VERSION ""

NS_ :

BS_:

BU_: XXX + HCU

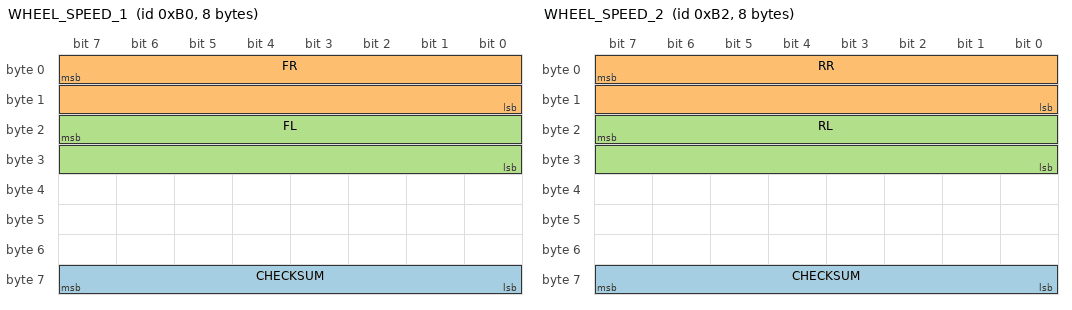
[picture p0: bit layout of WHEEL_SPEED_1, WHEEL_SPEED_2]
BO_ 176 WHEEL_SPEED_1: 8 XXX
 SG_ CHECKSUM : 63|8@0+ (1,0) [0|255] "" XXX
 SG_ FR : 7|16@0- (0.01,0) [0|250] "kph" XXX
 SG_ FL : 23|16@0- (0.01,0) [0|250] "kph" XXX

BO_ 178 WHEEL_SPEED_2: 8 XXX
 SG_ CHECKSUM : 63|8@0+ (1,0) [0|255] "" XXX
 SG_ RR : 7|16@0- (0.01,0) [0|250] "kph" XXX
 SG_ RL : 23|16@0- (0.01,0) [0|250] "kph" XXX

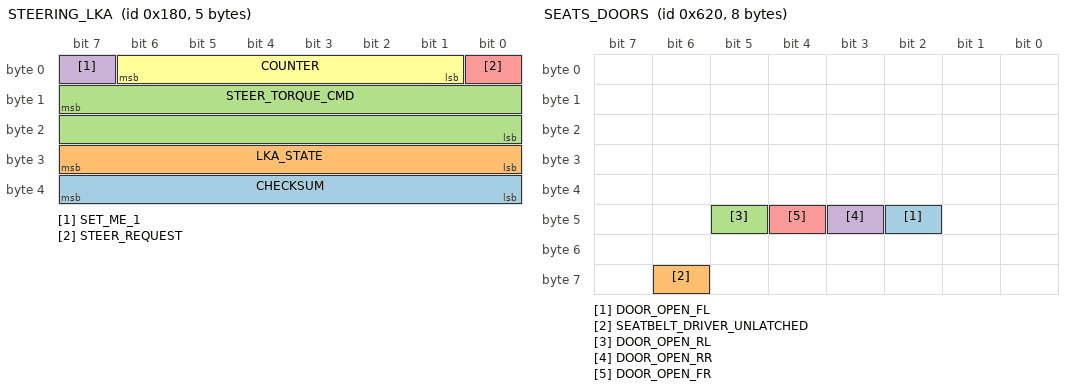
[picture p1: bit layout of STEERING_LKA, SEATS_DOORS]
BO_ 384 STEERING_LKA: 5 XXX
 SG_ CHECKSUM : 39|8@0+ (1,0) [0|255] "" XXX
 SG_ LKA_STATE : 31|8@0+ (1,0) [0|255] "" XXX
 SG_ STEER_TORQUE_CMD : 15|16@0- (1,0) [0|65535] "" XXX
 SG_ SET_ME_1 : 7|1@0+ (1,0) [0|1] "" XXX
 SG_ STEER_REQUEST : 0|1@0+ (1,0) [0|1] "" XXX
 SG_ COUNTER : 6|6@0+ (1,0) [0|63] "" XXX

BO_ 1568 SEATS_DOORS: 8 XXX
 SG_ DOOR_OPEN_FL : 42|1@0+ (1,0) [0|1] "" XXX
 SG_ SEATBELT_DRIVER_UNLATCHED : 62|1@0+ (1,0) [0|1] "" XXX
 SG_ DOOR_OPEN_RL : 45|1@0+ (1,0) [0|1] "" XXX
 SG_ DOOR_OPEN_RR : 43|1@0+ (1,0) [0|1] "" XXX
 SG_ DOOR_OPEN_FR : 44|1@0+ (1,0) [0|1] "" XXX

BO_ 37 STEER_ANGLE_SENSOR: 8 XXX
 SG_ STEER_ANGLE : 3|12@0- (1.5,0) [-500|500] "deg" XXX

BO_ 948 GEAR_PACKET: 8 XXX
 SG_ GEAR : 39|5@0+ (1,0) [0|15] "" XXX

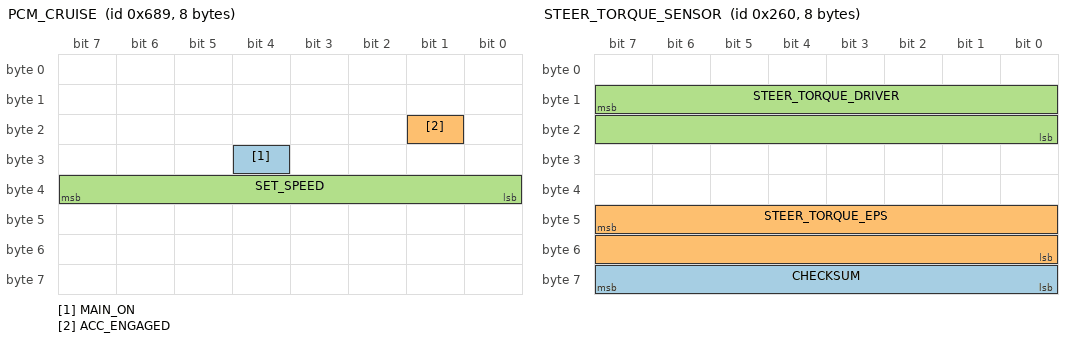
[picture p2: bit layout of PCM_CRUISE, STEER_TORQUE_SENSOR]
BO_ 1673 PCM_CRUISE: 8 XXX
 SG_ MAIN_ON : 28|1@0+ (1,0) [0|1] "" XXX
 SG_ ACC_ENGAGED : 17|1@0+ (1,0) [0|1] "" XXX
 SG_ SET_SPEED : 39|8@0+ (1,0) [0|255] "kph" XXX

BO_ 608 STEER_TORQUE_SENSOR: 8 XXX
 SG_ CHECKSUM : 63|8@0+ (1,0) [0|255] "" XXX
 SG_ STEER_TORQUE_EPS : 47|16@0- (1,0) [0|65535] "" XXX
 SG_ STEER_TORQUE_DRIVER : 15|16@0- (1,0) [-32768|32768] "" XXX

BO_ 184 BRAKE_MODULE3: 8 XXX
 SG_ BRAKE_PRESSURE : 43|12@0+ (1,0) [0|4095] "" XXX

BO_ 800 BRAKE_MODULE_2: 8 XXX
 SG_ BRAKE_PRESSED : 42|1@0+ (1,0) [0|1] "" XXX

BO_ 581 GAS_PEDAL: 8 XXX
 SG_ GAS_PEDAL : 16|8@1+ (1,0) [0|255] "" XXX

BO_ 1616 STEERING_LEVERS: 8 XXX
 SG_ TURN_SIGNALS : 31|2@0+ (1,0) [0|1] "" XXX

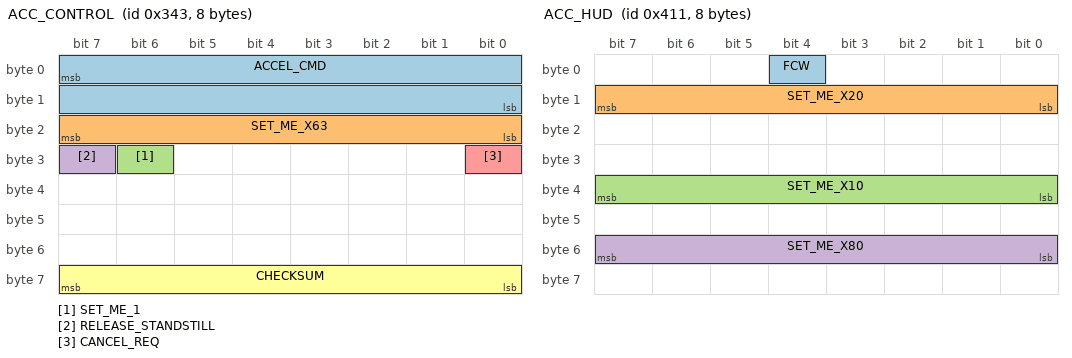
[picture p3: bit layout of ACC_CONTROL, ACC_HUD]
BO_ 835 ACC_CONTROL: 8 DSU
 SG_ ACCEL_CMD : 7|16@0- (0.001,0) [-20|20] "m/s2" HCU
 SG_ SET_ME_X63 : 23|8@0+ (1,0) [0|255] "" HCU
 SG_ SET_ME_1 : 30|1@0+ (1,0) [0|1] "" HCU
 SG_ RELEASE_STANDSTILL : 31|1@0+ (1,0) [0|1] "" HCU
 SG_ CANCEL_REQ : 24|1@0+ (1,0) [0|1] "" HCU
 SG_ CHECKSUM : 63|8@0+ (1,0) [0|255] "" XXX

BO_ 1041 ACC_HUD: 8 DSU
 SG_ FCW : 4|1@0+ (1,0) [0|1] "" XXX
 SG_ SET_ME_X20 : 15|8@0+ (1,0) [0|1] "" XXX
 SG_ SET_ME_X10 : 39|8@0+ (1,0) [0|1] "" XXX
 SG_ SET_ME_X80 : 55|8@0+ (1,0) [0|1] "" XXX

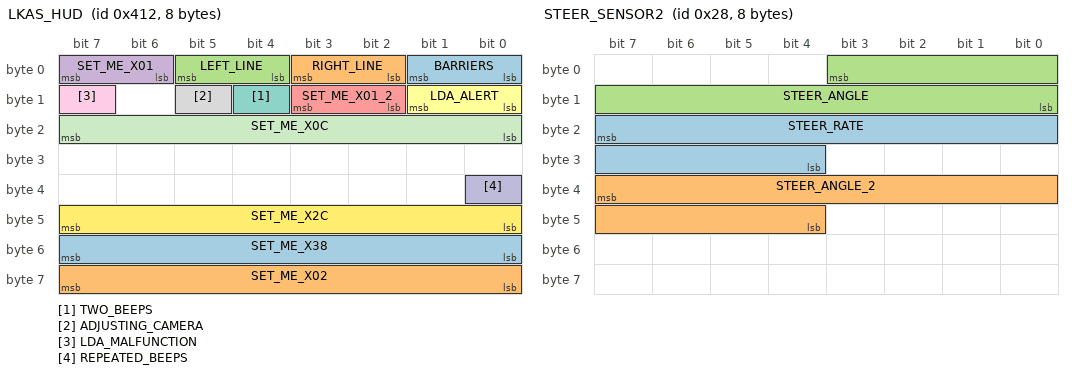
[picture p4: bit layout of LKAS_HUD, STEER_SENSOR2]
BO_ 1042 LKAS_HUD: 8 XXX
 SG_ BARRIERS : 1|2@0+ (1,0) [0|3] "" XXX
 SG_ RIGHT_LINE : 3|2@0+ (1,0) [0|3] "" XXX
 SG_ LEFT_LINE : 5|2@0+ (1,0) [0|3] "" XXX
 SG_ SET_ME_X01 : 7|2@0+ (1,0) [0|3] "" XXX
 SG_ SET_ME_X01_2 : 11|2@0+ (1,0) [0|3] "" XXX
 SG_ LDA_ALERT : 9|2@0+ (1,0) [0|3] "" XXX
 SG_ TWO_BEEPS : 12|1@0+ (1,0) [0|1] "" XXX
 SG_ ADJUSTING_CAMERA : 13|1@0+ (1,0) [0|1] "" XXX
 SG_ LDA_MALFUNCTION : 15|1@0+ (1,0) [0|1] "" XXX
 SG_ REPEATED_BEEPS : 32|1@0+ (1,0) [0|1] "" XXX
 SG_ SET_ME_X0C : 23|8@0+ (1,0) [0|1] "" XXX
 SG_ SET_ME_X2C : 47|8@0+ (1,0) [0|1] "" XXX
 SG_ SET_ME_X38 : 55|8@0+ (1,0) [0|1] "" XXX
 SG_ SET_ME_X02 : 63|8@0+ (1,0) [0|1] "" XXX

BO_ 560 BRAKE_MODULE2: 8 XXX
 SG_ BRAKE_PRESSED : 26|1@0+ (1,0) [0|1] "" XXX

BO_ 40 STEER_SENSOR2: 8 XXX
 SG_ STEER_RATE : 23|12@0- (1,0) [0|8191] "" XXX
 SG_ STEER_ANGLE_2 : 39|12@0- (1,0) [0|4095] "" XXX
 SG_ STEER_ANGLE : 3|12@0- (1,0) [0|8191] "" XXX

BO_ 548 BRAKE_MODULE: 8 XXX
 SG_ BRAKE_PRESSURE : 43|12@0+ (1,0) [0|4047] "" XXX
 SG_ BRAKE_PRESSED : 5|1@0+ (1,0) [0|1] "" XXX

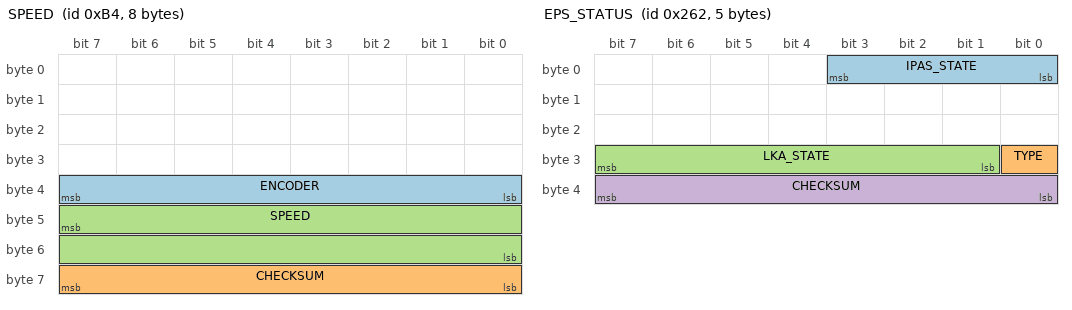
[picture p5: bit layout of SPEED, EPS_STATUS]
BO_ 180 SPEED: 8 XXX
 SG_ ENCODER : 39|8@0+ (1,0) [0|255] "" XXX
 SG_ CHECKSUM : 63|8@0+ (1,0) [0|255] "" XXX
 SG_ SPEED : 47|16@0+ (0.01,0) [0|250] "" XXX

BO_ 610 EPS_STATUS: 5 XXX
 SG_ IPAS_STATE : 3|4@0+ (1,0) [0|15] "" XXX
 SG_ TYPE : 24|1@0+ (1,0) [0|1] "" XXX
 SG_ LKA_STATE : 31|7@0+ (1,0) [0|127] "" XXX
 SG_ CHECKSUM : 39|8@0+ (1,0) [0|255] "" XXX

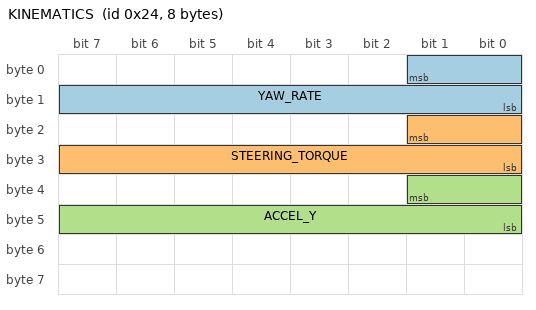
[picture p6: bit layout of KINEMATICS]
BO_ 36 KINEMATICS: 8 XXX
 SG_ YAW_RATE : 1|10@0+ (1,0) [0|3] "" XXX
 SG_ STEERING_TORQUE : 17|10@0+ (1,0) [0|255] "" XXX
 SG_ ACCEL_Y : 33|10@0+ (1,0) [0|3] "" XXX

BO_ 951 ESP_CONTROL: 8 XXX
 SG_ BRAKE_LIGHTS_ACC : 18|1@0+ (1,0) [0|1] "" XXX
 SG_ TC_DIABLED : 13|1@0+ (1,0) [0|1] "" XXX

VAL_ 948 GEAR 0 "D" 4 "N" 8 "R" 16 "P" ;
